# LPC54S018M register map
Vendor: nxp.com; File version: 1.0
CPU: CM4 r0p1, little endian, MPU, FPU, VTOR, 3 interrupt priority bits
Registers are 32-bit, read-write, reset 0x0 unless marked. A register's access mark holds for its fields unless they carry their own. Offsets are from the block's base; [hi:lo] are bit positions; {n}, {i} and the like mark numbered series.

## UTICK0 — LPC5411x Micro-tick Timer (UTICK)
Base 0x4000E000
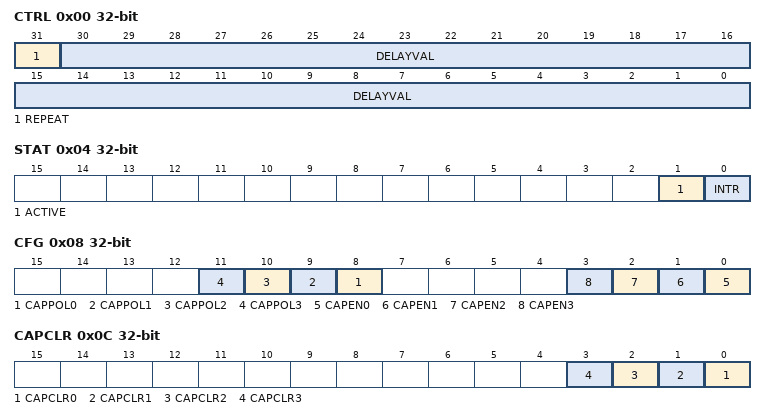
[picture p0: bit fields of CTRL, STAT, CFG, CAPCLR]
0x00 CTRL — Control register.
  [31] REPEAT — Repeat delay. 0 = One-time delay. 1 = Delay repeats continuously.
  [30:0] DELAYVAL — Tick interval value. The delay will be equal to DELAYVAL + 1 periods of the timer clock. The minimum usable value is 1, for a delay of 2 timer clocks. A value of 0 stops the timer.
0x04 STAT — Status register.
  [1] ACTIVE — Active flag. 0 = The Micro-Tick Timer is stopped. 1 = The Micro-Tick Timer is currently active.
  [0] INTR — Interrupt flag. 0 = No interrupt is pending. 1 = An interrupt is pending. A write of any value to this register clears this flag.
0x08 CFG — Capture configuration register.
  [n+8] CAPPOL{n} (n=0..3) — Capture Polarity {n}. 0 = Positive edge capture, 1 = Negative edge capture.
  [n] CAPEN{n} (n=0..3) — Enable Capture {n}. 1 = Enabled, 0 = Disabled.
0x0C CAPCLR wo reset not defined — Capture clear register.
  [n] CAPCLR{n} (n=0..3) — Clear capture {n}. Writing 1 to this bit clears the CAP{n} register value.
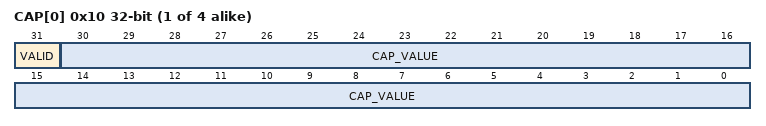
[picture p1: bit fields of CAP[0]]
{0x10+4i} CAP[{i}] (i=0..3) ro — Capture register .
  [31] VALID — Capture Valid. When 1, a value has been captured based on a transition of the related UTICK_CAPn pin. Cleared by writing to the related bit in the CAPCLR register.
  [30:0] CAP_VALUE — Capture value for the related capture event (UTICK_CAPn. Note: the value is 1 lower than the actual value of the Micro-tick Timer at the moment of the capture event.

## OTPC — This is the description of component otpc It is an eFUSE OTP (One Time Programmable memory) controller with APB bus interface. More details will follow.
Base 0x40015000
{0x10+4i} AESKEY[{i}] (i=0..7) ro reset not defined — Register for reading the AES key.
  [31:0] KEY — AES key.
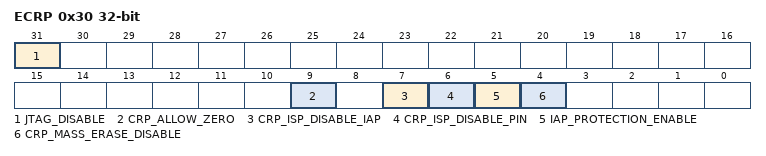
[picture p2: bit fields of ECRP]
0x30 ECRP ro reset not defined — ECRP options.
  [31] JTAG_DISABLE — 0 => Enable SWD/JTAG; 1 => Disable SWD/JTAG..
  [9] CRP_ALLOW_ZERO — This bit controls how 0 is treated when read as a ECRP value..
  [7] CRP_ISP_DISABLE_IAP — This bit controls the ability to re-invoke ISP using IAP routines.
  [6] CRP_ISP_DISABLE_PIN — This bit controls the ability to enter ISP mode using the ISP pin.
  [5] IAP_PROTECTION_ENABLE — This bit controls the ability to enable checking for ECRP in IAP functions.
  [4] CRP_MASS_ERASE_DISABLE — Disable or enable CRP mass erase.
0x38 USER0 ro reset not defined — User application specific options.
  [31:0] USER0 — User application specific option.
0x3C USER1 ro reset not defined — User application specific options.
  [31:0] USER1 — User application specific option.

## RIT — LPC54S60x/LPC5460x Repetitive Interrupt Timer(RIT)
Base 0x4002D000
0x00 COMPVAL reset 0xFFFFFFFF — Compare value LSB register
  [31:0] RICOMP
0x04 MASK — Mask LSB register
  [31:0] RIMASK — Mask register.
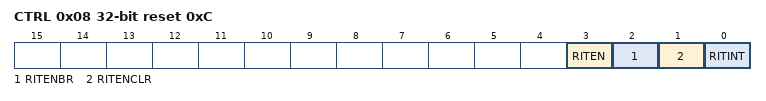
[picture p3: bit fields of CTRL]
0x08 CTRL reset 0xC — Control register
  [3] RITEN — Timer enable.
  [2] RITENBR — Timer enable for debug.
  [1] RITENCLR — Timer enable clear.
  [0] RITINT — Interrupt flag.
0x0C COUNTER — Counter LSB register
  [31:0] RICOUNTER — 32 LSBs of the up counter.
0x10 COMPVAL_H reset 0xFFFF — Compare value MSB register
  [15:0] RICOMP — Compare value MSB register.
0x14 MASK_H — Mask MSB register
  [15:0] RIMASK — Mask register.
0x1C COUNTER_H — Counter MSB register
  [15:0] RICOUNTER — 16 LSBs of the up counter.

## SMARTCARD0 — LPC5460x/LPC54S60x Smart Card Interface
Base 0x40036000
Same registers: SMARTCARD1 0x40037000
0x00 DLL reset 0x1 (RBR_THR_DLL view) — Divisor Latch LSB
  [7:0] DLLSB — The SCIn Divisor Latch LSB Register, along with the SCInDLM register, determines the baud rate of the SCIn.
0x00 RBR ro (RBR_THR_DLL view) — Receiver Buffer Register
  [7:0] RBR — The SCIn Receiver Buffer Register contains the oldest received byte in the SCIn Rx FIFO.
0x00 THR wo (RBR_THR_DLL view) — Transmit Holding Register
  [7:0] THR — Writing to the SCIn Transmit Holding Register causes the data to be stored in the SCIn transmit FIFO.
0x04 DLM (DLM_IER view) — Divisor Latch MSB
  [7:0] DLMSB — The SCIn Divisor Latch MSB Register, along with the DLL register, determines the baud rate of the SCIn.
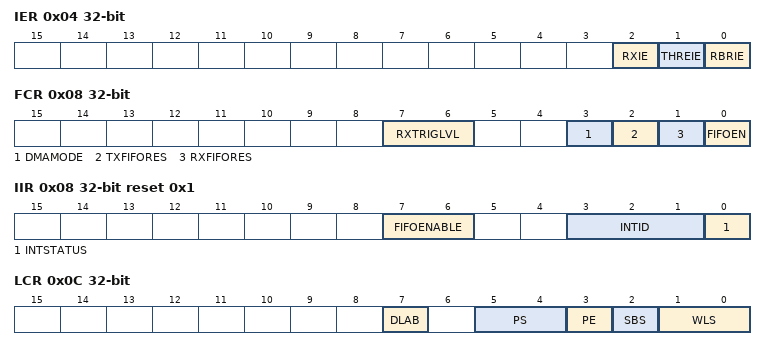
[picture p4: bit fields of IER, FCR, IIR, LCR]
0x04 IER (DLM_IER view) — Interrupt Enable Register
  [2] RXIE — RX Line Status Interrupt Enable.
  [1] THREIE — THRE Interrupt Enable.
  [0] RBRIE — RBR Interrupt Enable.
0x08 FCR wo (IIR_FCR view) — FIFO Control Register
  [7:6] RXTRIGLVL — RX Trigger Level.
  [3] DMAMODE — DMA Mode Select.
  [2] TXFIFORES — TX FIFO Reset.
  [1] RXFIFORES — RX FIFO Reset.
  [0] FIFOEN — FIFO Enable.
0x08 IIR ro reset 0x1 (IIR_FCR view) — Interrupt ID Register
  [7:6] FIFOENABLE — Copies of SCInFCR[0].
  [3:1] INTID — Interrupt identification.
  [0] INTSTATUS — Interrupt status.
0x0C LCR — Line Control Register
  [7] DLAB — Divisor Latch Access Bit.
  [5:4] PS — Parity Select.
  [3] PE — Parity Enable.
  [2] SBS — Stop Bit Select.
  [1:0] WLS — Word Length Select.
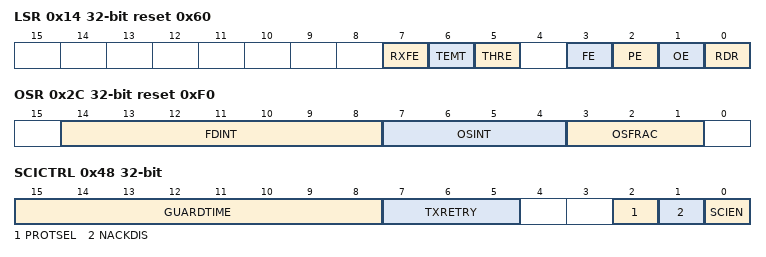
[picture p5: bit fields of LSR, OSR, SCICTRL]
0x14 LSR ro reset 0x60 — Line Status Register
  [7] RXFE — Error in RX FIFO.
  [6] TEMT — Transmitter Empty.
  [5] THRE — Transmitter Holding Register Empty.
  [3] FE — Framing Error.
  [2] PE — Parity Error.
  [1] OE — Overrun Error.
  [0] RDR — Receiver Data Ready.
0x1C SCR — Scratch Pad Register
  [7:0] PAD — A readable, writable byte.
0x2C OSR reset 0xF0 — Oversampling register
  [14:8] FDINT — These bits act as a more-significant extension of the OSint field, allowing an oversampling ratio up to 2048 as required by ISO7816-3.
  [7:4] OSINT — Integer part of the oversampling ratio, minus 1.
  [3:1] OSFRAC — Fractional part of the oversampling ratio, in units of 1/8th of an input clock period.
0x48 SCICTRL — Smart Card Interface control register
  [15:8] GUARDTIME — Extra guard time.
  [7:5] TXRETRY — Maximum number of retransmissions in case of a negative acknowledge (protocol T=0).
  [2] PROTSEL — Protocol selection as defined in the ISO7816-3 standard.
  [1] NACKDIS — NACK response disable.
  [0] SCIEN — Smart Card Interface Enable.
